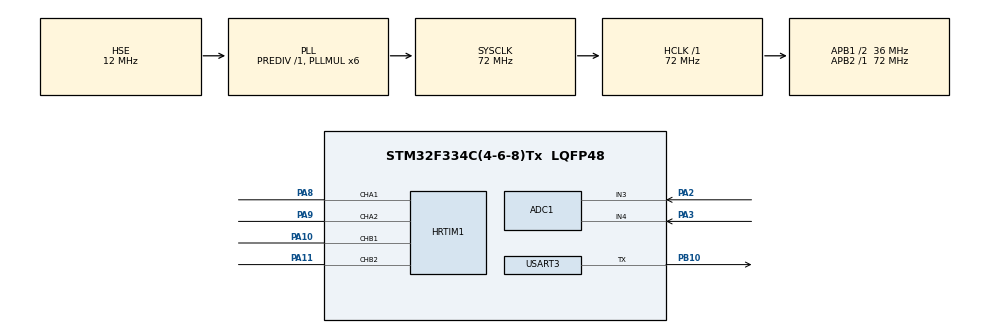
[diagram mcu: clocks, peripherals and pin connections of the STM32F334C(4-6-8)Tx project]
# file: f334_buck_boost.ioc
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ADC1.Channel-0\#ChannelRegularConversion=ADC_CHANNEL_4
ADC1.Channel-1\#ChannelRegularConversion=ADC_CHANNEL_3
ADC1.ContinuousConvMode=ENABLE
ADC1.DMAContinuousRequests=ENABLE
ADC1.EOCSelection=ADC_EOC_SEQ_CONV
ADC1.EnableInjectedConversion=DISABLE
ADC1.NbrOfConversion=2
ADC1.NbrOfConversionFlag=1
ADC1.Offset-0\#ChannelRegularConversion=0
ADC1.Offset-1\#ChannelRegularConversion=0
ADC1.OffsetNumber-0\#ChannelRegularConversion=ADC_OFFSET_NONE
ADC1.OffsetNumber-1\#ChannelRegularConversion=ADC_OFFSET_NONE
ADC1.Rank-0\#ChannelRegularConversion=1
ADC1.Rank-1\#ChannelRegularConversion=2
ADC1.SamplingTime-0\#ChannelRegularConversion=ADC_SAMPLETIME_19CYCLES_5
ADC1.SamplingTime-1\#ChannelRegularConversion=ADC_SAMPLETIME_19CYCLES_5
ADC1.master=1
Dma.ADC1.0.Direction=DMA_PERIPH_TO_MEMORY
Dma.ADC1.0.Instance=DMA1_Channel1
Dma.ADC1.0.MemDataAlignment=DMA_MDATAALIGN_HALFWORD
Dma.ADC1.0.MemInc=DMA_MINC_ENABLE
Dma.ADC1.0.Mode=DMA_CIRCULAR
Dma.ADC1.0.PeriphDataAlignment=DMA_PDATAALIGN_HALFWORD
Dma.ADC1.0.PeriphInc=DMA_PINC_DISABLE
Dma.ADC1.0.Priority=DMA_PRIORITY_VERY_HIGH
Dma.Request0=ADC1
HRTIM1.CompareUnit1-Output_TA1TA2=HRTIM_COMPAREUNIT_1
HRTIM1.CompareUnit1-Output_TB1TB2=HRTIM_COMPAREUNIT_1
HRTIM1.CompareUnit2-Output_TA1TA2=__NULL
HRTIM1.CompareUnit2-Output_TB1TB2=__NULL
HRTIM1.CompareUnit3-Output_TA1TA2=HRTIM_COMPAREUNIT_3
HRTIM1.CompareUnit3-Output_TB1TB2=HRTIM_COMPAREUNIT_3
HRTIM1.CompareValue1-Output_TA1TA2=10000
HRTIM1.CompareValue1-Output_TB1TB2=10000
HRTIM1.CompareValue3-Output_TA1TA2=61000
HRTIM1.CompareValue3-Output_TB1TB2=61000
HRTIM1.DeadTimeInsertion-Output_TA1TA2=HRTIM_TIMDEADTIMEINSERTION_ENABLED
HRTIM1.DeadTimeInsertion-Output_TB1TB2=HRTIM_TIMDEADTIMEINSERTION_ENABLED
HRTIM1.FallingValue-Output_TA1TA2=100
HRTIM1.FallingValue-Output_TB1TB2=100
HRTIM1.InterruptRequests1_Master=HRTIM_MASTER_IT_MREP
HRTIM1.NumberInterruptRequests_Master-MasterTimer=1
HRTIM1.NumberResetSource1-Output_TA1TA2=2
HRTIM1.NumberResetSource1-Output_TB1TB2=1
HRTIM1.NumberResetTrigger-Output_TA1TA2=1
HRTIM1.NumberResetTrigger-Output_TB1TB2=1
HRTIM1.NumberSetSource1-Output_TA1TA2=1
HRTIM1.NumberSetSource1-Output_TB1TB2=2
HRTIM1.NumberUpdateTrigger-Output_TA1TA2=1
HRTIM1.NumberUpdateTrigger-Output_TB1TB2=1
HRTIM1.Periode_MASTER=60000
HRTIM1.Periode_TA=65000
HRTIM1.Periode_TB=65000
HRTIM1.Polarity2-Output_TB1TB2=HRTIM_OUTPUTPOLARITY_HIGH
HRTIM1.PreloadEnable-MasterTimer=HRTIM_PRELOAD_ENABLED
HRTIM1.PreloadEnable-Output_TA1TA2=HRTIM_PRELOAD_ENABLED
HRTIM1.PreloadEnable-Output_TB1TB2=HRTIM_PRELOAD_ENABLED
HRTIM1.PrescalerRatio_TB=HRTIM_PRESCALERRATIO_MUL32
HRTIM1.RepetitionCounter-MasterTimer=7
HRTIM1.RepetitionUpdate-MasterTimer=HRTIM_UPDATEONREPETITION_ENABLED
HRTIM1.RepetitionUpdate-Output_TA1TA2=HRTIM_UPDATEONREPETITION_ENABLED
HRTIM1.RepetitionUpdate-Output_TB1TB2=HRTIM_UPDATEONREPETITION_ENABLED
HRTIM1.ResetOutput1_Source1-Output_TA1TA2=HRTIM_OUTPUTRESET_MASTERPER
HRTIM1.ResetOutput1_Source1-Output_TB1TB2=HRTIM_OUTPUTRESET_TIMCMP1
HRTIM1.ResetOutput1_Source2-Output_TA1TA2=HRTIM_OUTPUTRESET_TIMCMP3
HRTIM1.ResetTrigger1-Output_TA1TA2=HRTIM_TIMRESETTRIGGER_MASTER_PER
HRTIM1.ResetTrigger1-Output_TB1TB2=HRTIM_TIMRESETTRIGGER_MASTER_PER
HRTIM1.ResetUpdate-Output_TA1TA2=HRTIM_TIMUPDATEONRESET_DISABLED
HRTIM1.ResetUpdate-Output_TB1TB2=HRTIM_TIMUPDATEONRESET_DISABLED
HRTIM1.RisingValue-Output_TA1TA2=100
HRTIM1.RisingValue-Output_TB1TB2=100
HRTIM1.SetOutput1_Source1-Output_TA1TA2=HRTIM_OUTPUTSET_TIMCMP1
HRTIM1.SetOutput1_Source1-Output_TB1TB2=HRTIM_OUTPUTSET_MASTERPER
HRTIM1.SetOutput1_Source2-Output_TB1TB2=HRTIM_OUTPUTSET_TIMCMP3
HRTIM1.SetOutput1_Source3-Output_TB1TB2=HRTIM_OUTPUTSET_TIMCMP3
HRTIM1.UpdateTrigger1-Output_TA1TA2=HRTIM_TIMUPDATETRIGGER_MASTER
HRTIM1.UpdateTrigger1-Output_TB1TB2=HRTIM_TIMUPDATETRIGGER_MASTER
Mcu.Family=STM32F3
Mcu.Name=STM32F334C(4-6-8)Tx
Mcu.Package=LQFP48
NVIC.DMA1_Channel1_IRQn=true\:0\:0\:false\:false\:true\:false\:true
NVIC.HRTIM1_Master_IRQn=true\:4\:0\:true\:false\:true\:true\:true
NVIC.PriorityGroup=NVIC_PRIORITYGROUP_4
PA10.Mode=Output_TB1TB2
PA10.Signal=HRTIM1_CHB1
PA11.Mode=Output_TB1TB2
PA11.Signal=HRTIM1_CHB2
PA13.Mode=Serial_Wire
PA13.Signal=SYS_JTMS-SWDIO
PA14.Mode=Serial_Wire
PA14.Signal=SYS_JTCK-SWCLK
PA2.Mode=IN3-Single-Ended
PA2.Signal=ADC1_IN3
PA3.Mode=IN4-Single-Ended
PA3.Signal=ADC1_IN4
PA8.Mode=Output_TA1TA2
PA8.Signal=HRTIM1_CHA1
PA9.Mode=Output_TA1TA2
PA9.Signal=HRTIM1_CHA2
PB10.Mode=Half_duplex(single_wire_mode)
PB10.Signal=USART3_TX
PF0\ /\ OSC_IN.Mode=HSE-External-Clock-Source
PF0\ /\ OSC_IN.Signal=RCC_OSC_IN
ProjectManager.HeapSize=0x200
ProjectManager.StackSize=0x400
ProjectManager.TargetToolchain=MDK-ARM V5.32
RCC.AHBFreq_Value=72000000
RCC.APB1CLKDivider=RCC_HCLK_DIV2
RCC.APB1Freq_Value=36000000
RCC.APB1TimFreq_Value=72000000
RCC.APB2Freq_Value=72000000
RCC.APB2TimFreq_Value=72000000
RCC.CortexFreq_Value=72000000
RCC.HCLKFreq_Value=72000000
RCC.HRTIMSelection=RCC_HRTIM1CLK_PLLCLK
RCC.HSE_VALUE=12000000
RCC.HSI_VALUE=8000000
RCC.LSE_VALUE=32768
RCC.PLLMUL=RCC_PLL_MUL6
RCC.PLLSourceVirtual=RCC_PLLSOURCE_HSE
RCC.SYSCLKFreq_VALUE=72000000
RCC.SYSCLKSourceVirtual=RCC_SYSCLKSOURCE_PLLCLK
USART3.BaudRate=115200
USART3.Mode=MODE_TX
USART3.OneBitSampling=UART_ONE_BIT_SAMPLE_DISABLE
USART3.SwapParam=ADVFEATURE_SWAP_DISABLE
USART3.VirtualMode-Half_duplex(single_wire_mode)=VM_ASYNC
VP_HRTIM1_VS_hrtimMasterTimerNoOutput.Mode=MasterTimer
board=custom

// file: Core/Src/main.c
/* USER CODE BEGIN Header */
/**
  ******************************************************************************
  * @file           : main.c
  * @brief          : Main program body
  ******************************************************************************
  * @attention
  *
  * <h2><center>&copy; Copyright (c) 2021 STMicroelectronics.
  * All rights reserved.</center></h2>
  *
  * This software component is licensed by ST under BSD 3-Clause license,
  * the "License"; You may not use this file except in compliance with the
  * License. You may obtain a copy of the License at:
  *                        opensource.org/licenses/BSD-3-Clause
  *
  ******************************************************************************
  */
/* USER CODE END Header */
#include "main.h"
#include "adc.h"
#include "dma.h"
#include "hrtim.h"
#include "hrtim.h"
#include "usart.h"
#include "gpio.h"

/* USER CODE BEGIN Includes */
#include "drv_BridgeHW.h"
#include "drv_ADCSense.h"
/* USER CODE END Includes */

void SystemClock_Config(void);

/* USER CODE BEGIN 0 */
uint16_t duty=20000;
/* USER CODE END 0 */

int main(void)
{

  /* MCU Configuration--------------------------------------------------------*/

  /* Reset of all peripherals, Initializes the Flash interface and the Systick. */
  HAL_Init();

  /* USER CODE BEGIN Init */
	HAL_Delay(100);
  /* USER CODE END Init */

  /* Configure the system clock */
  SystemClock_Config();

  /* Initialize all configured peripherals */
  MX_GPIO_Init();
  MX_HRTIM1_Init();
  MX_DMA_Init();
  MX_ADC1_Init();
  MX_USART3_UART_Init();
  /* USER CODE BEGIN 2 */
  ADCSense_Init(); // 需要比Bridge初始化早
  Bridge_Init();
  /* USER CODE END 2 */

  /* Infinite loop */
  /* USER CODE BEGIN WHILE */
  while (1)
  {

		//hhrtim1.Instance->sTimerxRegs[1].CMP1xR = duty;
		HAL_Delay(100);
    /* USER CODE END WHILE */

  }
}

void SystemClock_Config(void)
{
  RCC_OscInitTypeDef RCC_OscInitStruct = {0};
  RCC_ClkInitTypeDef RCC_ClkInitStruct = {0};
  RCC_PeriphCLKInitTypeDef PeriphClkInit = {0};

  /** Initializes the RCC Oscillators according to the specified parameters
  * in the RCC_OscInitTypeDef structure.
  */
  RCC_OscInitStruct.OscillatorType = RCC_OSCILLATORTYPE_HSE;
  RCC_OscInitStruct.HSEState = RCC_HSE_BYPASS;
  RCC_OscInitStruct.HSEPredivValue = RCC_HSE_PREDIV_DIV1;
  RCC_OscInitStruct.HSIState = RCC_HSI_ON;
  RCC_OscInitStruct.PLL.PLLState = RCC_PLL_ON;
  RCC_OscInitStruct.PLL.PLLSource = RCC_PLLSOURCE_HSE;
  RCC_OscInitStruct.PLL.PLLMUL = RCC_PLL_MUL6;
  if (HAL_RCC_OscConfig(&RCC_OscInitStruct) != HAL_OK)
  {
    Error_Handler();
  }
  /** Initializes the CPU, AHB and APB buses clocks
  */
  RCC_ClkInitStruct.ClockType = RCC_CLOCKTYPE_HCLK|RCC_CLOCKTYPE_SYSCLK
                              |RCC_CLOCKTYPE_PCLK1|RCC_CLOCKTYPE_PCLK2;
  RCC_ClkInitStruct.SYSCLKSource = RCC_SYSCLKSOURCE_PLLCLK;
  RCC_ClkInitStruct.AHBCLKDivider = RCC_SYSCLK_DIV1;
  RCC_ClkInitStruct.APB1CLKDivider = RCC_HCLK_DIV2;
  RCC_ClkInitStruct.APB2CLKDivider = RCC_HCLK_DIV1;

  if (HAL_RCC_ClockConfig(&RCC_ClkInitStruct, FLASH_LATENCY_2) != HAL_OK)
  {
    Error_Handler();
  }
  PeriphClkInit.PeriphClockSelection = RCC_PERIPHCLK_HRTIM1|RCC_PERIPHCLK_ADC12;
  PeriphClkInit.Adc12ClockSelection = RCC_ADC12PLLCLK_DIV1;
  PeriphClkInit.Hrtim1ClockSelection = RCC_HRTIM1CLK_PLLCLK;
  if (HAL_RCCEx_PeriphCLKConfig(&PeriphClkInit) != HAL_OK)
  {
    Error_Handler();
  }
}

void Error_Handler(void)
{
  __disable_irq();
  while (1)
  {
  }
}

/************************ (C) COPYRIGHT STMicroelectronics *****END OF FILE****/
